# McPDM_DSP register map
Vendor: Texas Instruments
Peripheral module from a debugger description file (folder omap4430).
Registers are 32-bit, access per field, reset 0x0 unless marked. A register's access mark holds for its fields unless they carry their own. Offsets are as the file gives them; lines under a group give offsets from that group; [hi:lo] are bit positions; {n}, {i} and the like mark numbered series; 'fields as' and 'values as' point back to an identical list; <NAME> marks a mode.

## McPDM_DSP
0x00 MCPDM_REVISION ro reset not defined — IP revision identifier (X.Y.R) used by software to track features, bugs, and compatibility
  [31:0] REVISION — IP revision
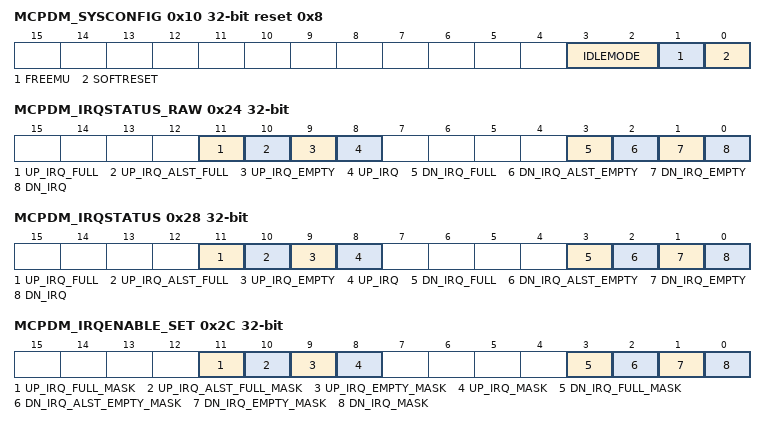
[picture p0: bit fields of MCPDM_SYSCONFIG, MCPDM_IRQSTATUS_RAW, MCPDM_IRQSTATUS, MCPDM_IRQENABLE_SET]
0x10 MCPDM_SYSCONFIG reset 0x8 — This register allows controlling various parameters of the OCP interface.
  [3:2] IDLEMODE rw — Configuration of the idle mode.
    0=Force- idle. idle request is acknowledged unconditionally and immediately. No wake-up capability.; 1=No-idle. Idle request is never acknowledged. No wake-up capability.; 2=Smart-idle. The acknowledgment to an idle request is given based on the internal activity. No wake-up capability.; 3=Idle request acknowledged pending internal conditions, asynchronous wake-up enabled. Wakeup capability.
  [1] FREEMU rw — Sensitivity to emulation (debug) suspend input signal.
    0=McPDM module is sensitive to emulation suspend; 1=McPDM module is not sensitive to emulation suspend
  [0] SOFTRESET rw — McPDM software Reset.
    0=SOFTRESET_0_w (No Action); 0=SOFTRESET_0_r (No ongoing software reset); 1=SOFTRESET_1_r (Reset is ongoing); 1=SOFTRESET_1_w (Start software reset)
0x24 MCPDM_IRQSTATUS_RAW — Interrupt request raw status register (for debug purpose).
  [11] UP_IRQ_FULL rw — FIFO-uplink-full signal appears when a write access is performed and the FIFO uplink is already full.
    0=UP_IRQ_FULL_0_r (No event pending); 0=UP_IRQ_FULL_0_w (No action); 1=UP_IRQ_FULL_1_w (Set the event (for debug)); 1=UP_IRQ_FULL_1_r (Event pending)
  [10] UP_IRQ_ALST_FULL rw — FIFO uplink almost-full signal appears when the FIFO uplink contains (FIFO uplink size – 1) elements.
    0=UP_IRQ_ALST_FULL_0_r (No event pending); 0=UP_IRQ_ALST_FULL_0_w (No action); 1=UP_IRQ_ALST_FULL_1_w (Set the event (for debug)); 1=UP_IRQ_ALST_FULL_1_r (Event pending)
  [9] UP_IRQ_EMPTY rw — FIFO uplink empty signal appears when a read access is done and FIFO uplink already empty.
    0=UP_IRQ_EMPTY_0_r (No event pending); 0=UP_IRQ_EMPTY_0_w (No action); 1=UP_IRQ_EMPTY_1_w (Set the event (for debug)); 1=UP_IRQ_EMPTY_1_r (Event pending)
  [8] UP_IRQ rw — FIFO uplink interrupt appears when the number of data present in the FIFO uplink has reached the value of the FIFO uplink threshold.
    0=UP_IRQ_0_r (No event pending); 0=UP_IRQ_0_w (No action); 1=UP_IRQ_1_w (Set the event (for debug)); 1=UP_IRQ_1_r (Event pending)
  [3] DN_IRQ_FULL rw — FIFO downlink full signal appears when the FIFO uplink is full and another a write access is performed.
    0=DN_IRQ_FULL_0_r (No event pending); 0=DN_IRQ_FULL_0_w (No action); 1=DN_IRQ_FULL_1_w (Set the event (for debug)); 1=DN_IRQ_FULL_1_r (Event pending)
  [2] DN_IRQ_ALST_EMPTY rw — FIFO downlink almost empty signal appears when the FIFO downlink contains only one element.
    0=DN_IRQ_ALST_EMPTY_0_r (No event pending); 0=DN_IRQ_ALST_EMPTY_0_w (No action); 1=DN_IRQ_ALST_EMPTY_1_w (Set the event (for debug)); 1=DN_IRQ_ALST_EMPTY_1_r (Event pending)
  [1] DN_IRQ_EMPTY rw — FIFO-downlink-empty signal appears when read access is performed and FIFO downlink is already empty.
    0=DN_IRQ_EMPTY_0_r (No event pending); 0=DN_IRQ_EMPTY_0_w (No action); 1=DN_IRQ_EMPTY_1_w (Set the event (for debug)); 1=DN_IRQ_EMPTY_1_r (Event pending)
  [0] DN_IRQ rw — FIFO downlink status is set when the number of data is below the FIFO downlink threshold value.
    0=DN_IRQ_0_r (No event pending); 0=DN_IRQ_0_w (No action); 1=DN_IRQ_1_w (Set the event (for debug)); 1=DN_IRQ_1_r (Event pending)
0x28 MCPDM_IRQSTATUS access not given — Interrupt request status register.
  [11] UP_IRQ_FULL rw — FIFO-uplink-full signal appears when a write access is performed and the FIFO uplink is already full.
    0=UP_IRQ_FULL_0_r (No event pending); 0=UP_IRQ_FULL_0_w (No action); 1=UP_IRQ_FULL_1_w (Clear pending event); 1=UP_IRQ_FULL_1_r (Event pending)
  [10] UP_IRQ_ALST_FULL rw — FIFO uplink almost-full signal appears when the FIFO uplink contains (FIFO uplink size – 1) elements.
    0=UP_IRQ_ALST_FULL_0_r (No event pending); 0=UP_IRQ_ALST_FULL_0_w (No action); 1=UP_IRQ_ALST_FULL_1_w (Clear pending event); 1=UP_IRQ_ALST_FULL_1_r (Event pending)
  [9] UP_IRQ_EMPTY rw — FIFO uplink empty signal appears when a read access is done and FIFO uplink already empty.
    0=UP_IRQ_EMPTY_0_r (No event pending); 0=UP_IRQ_EMPTY_0_w (No action); 1=UP_IRQ_EMPTY_1_w (Clear pending event); 1=UP_IRQ_EMPTY_1_r (Event pending)
  [8] UP_IRQ rw — FIFO uplink interrupt appears when the number of data present in the FIFO uplink has reached the value of the FIFO uplink threshold.
    0=UP_IRQ_0_r (No event pending); 0=UP_IRQ_0_w (No action); 1=UP_IRQ_1_w (Clear pending event); 1=UP_IRQ_1_r (Event pending)
  [3] DN_IRQ_FULL rw — FIFO downlink full signal appears when the FIFO uplink is full and another a write access is performed.
    0=DN_IRQ_FULL_0_r (No event pending); 0=DN_IRQ_FULL_0_w (No action); 1=DN_IRQ_FULL_1_w (Clear pending event); 1=DN_IRQ_FULL_1_r (Event pending)
  [2] DN_IRQ_ALST_EMPTY rw — FIFO downlink almost empty signal appears when the FIFO downlink contains only one element.
    0=DN_IRQ_ALST_EMPTY_0_r (No event pending); 0=DN_IRQ_ALST_EMPTY_0_w (No action); 1=DN_IRQ_ALST_EMPTY_1_w (Clear pending event); 1=DN_IRQ_ALST_EMPTY_1_r (Event pending)
  [1] DN_IRQ_EMPTY — FIFO-downlink-empty signal appears when read access is performed and FIFO downlink is already empty. (access RW W1toSet)
    0=DN_IRQ_EMPTY_0_r (No event pending); 0=DN_IRQ_EMPTY_0_w (No action); 1=DN_IRQ_EMPTY_1_w (Clear pending event); 1=DN_IRQ_EMPTY_1_r (Event pending)
  [0] DN_IRQ rw — FIFO downlink status is set when the number of data is below the FIFO downlink threshold value.
    0=DN_IRQ_0_r (No event pending); 0=DN_IRQ_0_w (No action); 1=DN_IRQ_1_w (Clear pending event); 1=DN_IRQ_1_r (Event pending)
0x2C MCPDM_IRQENABLE_SET — Interrupt request enable set register.
  [11] UP_IRQ_FULL_MASK rw — FIFO-uplink-full event interrupt enabling bit.
    0=UP_IRQ_FULL_MASK_0_r (Interrupt disabled); 0=UP_IRQ_FULL_MASK_0_w (No action); 1=UP_IRQ_FULL_MASK_1_w (Enable interrupt); 1=UP_IRQ_FULL_MASK_1_r (Interrupt enabled)
  [10] UP_IRQ_ALST_FULL_MASK rw — FIFO-uplink-almost-full event interrupt enabling bit.
    0=UP_IRQ_ALST_FULL_MASK_0_r (Interrupt disabled); 0=UP_IRQ_ALST_FULL_MASK_0_w (No action); 1=UP_IRQ_ALST_FULL_MASK_1_w (Enable interrupt); 1=UP_IRQ_ALST_FULL_MASK_1_r (Interrupt enabled)
  [9] UP_IRQ_EMPTY_MASK rw — FIFO-uplink-empty event interrupt enabling bit.
    0=UP_IRQ_EMPTY_MASK_0_r (Interrupt disabled); 0=UP_IRQ_EMPTY_MASK_0_w (No action); 1=UP_IRQ_EMPTY_MASK_1_w (Enable interrupt); 1=UP_IRQ_EMPTY_MASK_1_r (Interrupt enabled)
  [8] UP_IRQ_MASK rw — FIFO-uplink-read-request event interrupt enabling bit.
    0=UP_IRQ_MASK_0_r (Interrupt disabled); 0=UP_IRQ_MASK_0_w (No action); 1=UP_IRQ_MASK_1_w (Enable interrupt); 1=UP_IRQ_MASK_1_r (Interrupt enabled)
  [3] DN_IRQ_FULL_MASK rw — FIFO-downlink-full event interrupt enabling bit.
    0=DN_IRQ_FULL_MASK_0_r (Interrupt disabled); 0=DN_IRQ_FULL_MASK_0_w (No action); 1=DN_IRQ_FULL_MASK_1_w (Enable interrupt); 1=DN_IRQ_FULL_MASK_1_r (Interrupt enabled)
  [2] DN_IRQ_ALST_EMPTY_MASK rw — FIFO downlink almost-empty event interrupt enabling bit.
    0=DN_IRQ_ALST_EMPTY_MASK_0_r (Interrupt disabled); 0=DN_IRQ_ALST_EMPTY_MASK_0_w (No action); 1=DN_IRQ_ALST_EMPTY_MASK_1_w (Enable interrupt); 1=DN_IRQ_ALST_EMPTY_MASK_1_r (Interrupt enabled)
  [1] DN_IRQ_EMPTY_MASK rw — FIFO-downlink-empty event interrupt enabling bit.
    0=DN_IRQ_EMPTY_MASK_0_r (Interrupt disabled); 0=DN_IRQ_EMPTY_MASK_0_w (No action); 1=DN_IRQ_EMPTY_MASK_1_w (Enable interrupt); 1=DN_IRQ_EMPTY_MASK_1_r (Interrupt enabled)
  [0] DN_IRQ_MASK rw — FIFO downlink write-request event interrupt enabling bit.
    0=DN_IRQ_MASK_0_r (Interrupt disabled); 0=DN_IRQ_MASK_0_w (No action); 1=DN_IRQ_MASK_1_w (Enable interrupt); 1=DN_IRQ_MASK_1_r (Interrupt enabled)
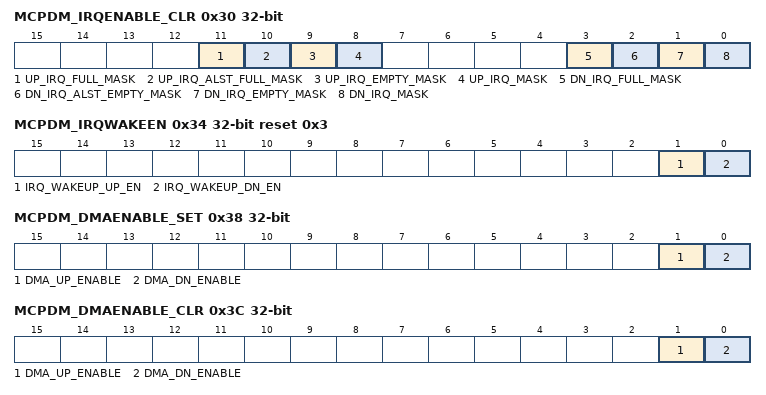
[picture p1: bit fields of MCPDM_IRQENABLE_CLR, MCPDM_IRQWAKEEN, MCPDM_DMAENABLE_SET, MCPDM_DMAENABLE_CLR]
0x30 MCPDM_IRQENABLE_CLR — Interrupt request enable clear register.
  [11] UP_IRQ_FULL_MASK rw — FIFO-uplink-full event interrupt disabling bit.
    0=UP_IRQ_FULL_MASK_0_r (Interrupt disabled); 0=UP_IRQ_FULL_MASK_0_w (No action); 1=UP_IRQ_FULL_MASK_1_w (Disable interrupt); 1=UP_IRQ_FULL_MASK_1_r (Interrupt enabled)
  [10] UP_IRQ_ALST_FULL_MASK rw — FIFO-uplink-almost-full event interrupt disabling bit.
    0=UP_IRQ_ALST_FULL_MASK_0_r (Interrupt disabled); 0=UP_IRQ_ALST_FULL_MASK_0_w (No action); 1=UP_IRQ_ALST_FULL_MASK_1_w (Disable interrupt); 1=UP_IRQ_ALST_FULL_MASK_1_r (Interrupt enabled)
  [9] UP_IRQ_EMPTY_MASK rw — FIFO-uplink-empty event interrupt disabling bit.
    0=UP_IRQ_EMPTY_MASK_0_r (Interrupt disabled); 0=UP_IRQ_EMPTY_MASK_0_w (No action); 1=UP_IRQ_EMPTY_MASK_1_w (Disable interrupt); 1=UP_IRQ_EMPTY_MASK_1_r (Interrupt enabled)
  [8] UP_IRQ_MASK rw — FIFO-uplink-read-request event interrupt disabling bit.
    0=UP_IRQ_MASK_0_r (Interrupt disabled); 0=UP_IRQ_MASK_0_w (No action); 1=UP_IRQ_MASK_1_w (Disable interrupt); 1=UP_IRQ_MASK_1_r (Interrupt enabled)
  [3] DN_IRQ_FULL_MASK rw — FIFO-downlink-full event interrupt disabling bit.
    0=DN_IRQ_FULL_MASK_0_r (Interrupt disabled); 0=DN_IRQ_FULL_MASK_0_w (No action); 1=DN_IRQ_FULL_MASK_1_w (Disable interrupt); 1=DN_IRQ_FULL_MASK_1_r (Interrupt enabled)
  [2] DN_IRQ_ALST_EMPTY_MASK rw — FIFO downlink almost-empty event interrupt disabling bit.
    0=DN_IRQ_ALST_EMPTY_MASK_0_r (Interrupt disabled); 0=DN_IRQ_ALST_EMPTY_MASK_0_w (No action); 1=DN_IRQ_ALST_EMPTY_MASK_1_w (Disable interrupt); 1=DN_IRQ_ALST_EMPTY_MASK_1_r (Interrupt enabled)
  [1] DN_IRQ_EMPTY_MASK rw — FIFO-downlink-empty event interrupt disabling bit.
    0=DN_IRQ_EMPTY_MASK_0_r (Interrupt disabled); 0=DN_IRQ_EMPTY_MASK_0_w (No action); 1=DN_IRQ_EMPTY_MASK_1_w (Disable interrupt); 1=DN_IRQ_EMPTY_MASK_1_r (Interrupt enabled)
  [0] DN_IRQ_MASK rw — FIFO downlink write-request event interrupt disabling bit.
    0=DN_IRQ_MASK_0_r (Interrupt disabled); 0=DN_IRQ_MASK_0_w (No action); 1=DN_IRQ_MASK_1_w (Disable interrupt); 1=DN_IRQ_MASK_1_r (Interrupt enabled)
0x34 MCPDM_IRQWAKEEN reset 0x3 — Interrupt request wake-up enable register.
  [1] IRQ_WAKEUP_UP_EN rw — Enabling/disabling bit for wake-up request generation upon a FIFO-uplink-read-request event.
    0=Disable the wake-up request generation; 1=Enable the wake-up request generation
  [0] IRQ_WAKEUP_DN_EN rw — Enabling/disabling bit for wake-up by FIFO downlink write-request event.
    values as IRQ_WAKEUP_UP_EN
0x38 MCPDM_DMAENABLE_SET — DMA request enable set register.
  [1] DMA_UP_ENABLE rw — Uplink path DMA request generation enabling bit.
    0=DMA_UP_ENABLE_0_r (DMA request disabled); 0=DMA_UP_ENABLE_0_w (No action); 1=DMA_UP_ENABLE_1_w (Enable DMA request); 1=DMA_UP_ENABLE_1_r (DMA request enabled)
  [0] DMA_DN_ENABLE rw — Downlink path DMA request generation enabling bit.
    0=DMA_DN_ENABLE_0_r (DMA request disabled); 0=DMA_DN_ENABLE_0_w (No action); 1=DMA_DN_ENABLE_1_w (Enable DMA request); 1=DMA_DN_ENABLE_1_r (DMA request enabled)
0x3C MCPDM_DMAENABLE_CLR — DMA request enable clear register.
  [1] DMA_UP_ENABLE rw — Uplink path DMA request generation disabling bit.
    0=DMA_UP_ENABLE_0_r (DMA request disabled); 0=DMA_UP_ENABLE_0_w (No action); 1=DMA_UP_ENABLE_1_w (Disable DMA request); 1=DMA_UP_ENABLE_1_r (DMA request enabled)
  [0] DMA_DN_ENABLE rw — Downlink path DMA request generation disabling bit.
    0=DMA_DN_ENABLE_0_r (DMA request disabled); 0=DMA_DN_ENABLE_0_w (No action); 1=DMA_DN_ENABLE_1_w (Disable DMA request); 1=DMA_DN_ENABLE_1_r (DMA request enabled)
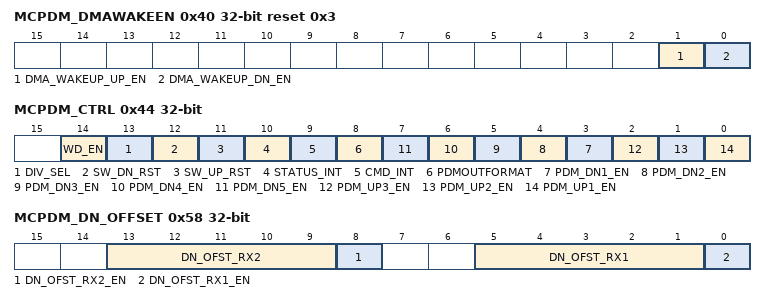
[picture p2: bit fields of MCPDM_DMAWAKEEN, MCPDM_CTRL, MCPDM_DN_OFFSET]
0x40 MCPDM_DMAWAKEEN reset 0x3 — DMA request wake-up enable register.
  [1] DMA_WAKEUP_UP_EN rw — Enabling/disabling bit for wake-up request generation upon an uplink path DMA request.
    values as MCPDM_IRQWAKEEN.IRQ_WAKEUP_UP_EN
  [0] DMA_WAKEUP_DN_EN rw — Enabling/disabling bit for wake-up request generation upon a downlink path DMA request.
    values as MCPDM_IRQWAKEEN.IRQ_WAKEUP_UP_EN
0x44 MCPDM_CTRL — MCPDM control register.
  [14] WD_EN rw — This bit is used to enable or disable the pulse-density modulator watchdog logic.0x0: Disabled (default after reset)0x1: Enabled
  [13] DIV_SEL rw — Multiply by 2 the FS of the uplink path0x0: FS = 88.2 kHz, or 96 kHz0x1: FS = 176.4 kHz, or 192 kHz
  [12] SW_DN_RST rw — Software reset of the downlink path.
    0=Downlink path is out of reset; 1=Reset of the downlink path
  [11] SW_UP_RST rw — Software reset of the uplink path.
    0=Uplink path is out of reset; 1=Reset of the uplink path
  [10] STATUS_INT rw — Status channel enabling/disabling bit.
    0=Status channel is disabled; 1=Status channel is enabled
  [9] CMD_INT rw — Command channel enabling/disabling bit.
    0=Command channel is disabled; 1=Command channel is enabled
  [8] PDMOUTFORMAT rw — Audio format selection:
    0=Left justification with eight 0-bit padding added for the less significant bits; 1=Right justification with sign bit extended to the 8 MSBs
  [n+2] PDM_DN{n}_EN rw (n=1..5) — Audio downlink channel {n} enabling/disabling bit
  [2] PDM_UP3_EN rw — Audio uplink channel 3 enabling/disabling bit
  [1] PDM_UP2_EN rw — Audio uplink channel 2 enabling/disabling bit
  [0] PDM_UP1_EN rw — Audio uplink channel 1 enabling/disabling bit
0x48 MCPDM_DN_DATA rw — Downlink path data register.
  [31:0] DN_DATA — Downlink path data value
0x4C MCPDM_UP_DATA ro — Uplink path data register.
  [31:0] UP_DATA — Uplink path data value
0x50 MCPDM_FIFO_CTRL_DN reset 0x2 — FIFO downlink control register.
  [3:0] DN_TRESH rw — FIFO downlink threshold value
0x54 MCPDM_FIFO_CTRL_UP reset 0x2 — FIFO uplink control register.
  [3:0] UP_TRESH rw — FIFO uplink threshold value
0x58 MCPDM_DN_OFFSET
  [13:9] DN_OFST_RX2 rw — Offset value for the audio downlink channel 2
  [8] DN_OFST_RX2_EN rw — Offset cancellation feature enabling/disabling bit for the audio downlink channel 2.
    0=Offset cancellation disabled; 1=Offset cancellation enabled
  [5:1] DN_OFST_RX1 rw — Offset value for the audio downlink channel 1
  [0] DN_OFST_RX1_EN rw — Offset cancellation feature enabling/disabling bit for the audio downlink channel 1.
    values as DN_OFST_RX2_EN
